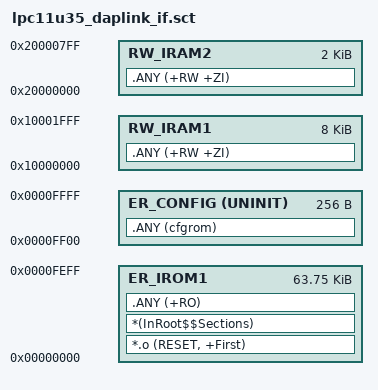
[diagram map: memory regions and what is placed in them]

LR_IROM1 0x00000000 0xFF00  {    ; load region size_region (64k - 256)

  ER_IROM1 0x00000000 0xFF00  {  ; load address = execution address   *.o (RESET, +First)
    *.o (RESET, +First)
    *(InRoot$$Sections)
    .ANY (+RO)
  }
  
  RW_IRAM1 0x10000000 0x2000  {
    .ANY (+RW +ZI)
  }
  
  RW_IRAM2 0x20000000 0x800  {
    .ANY (+RW +ZI)
  } 
  
}
LR_CONFIG 0x0000FF00 0x100 {	 ; reserve last sector for config data
  ER_CONFIG 0x0000FF00 UNINIT 0x100 {
    .ANY (cfgrom)
  }
}
